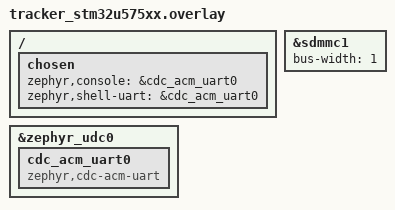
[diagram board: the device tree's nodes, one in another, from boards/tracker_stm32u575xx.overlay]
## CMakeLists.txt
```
cmake_minimum_required(VERSION 3.20.0)
find_package(Zephyr REQUIRED HINTS $ENV{ZEPHYR_BASE})
project(sdcard_usb_sample)

target_sources(app PRIVATE src/main.c)
```

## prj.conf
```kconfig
# Console over USB CDC ACM
CONFIG_LOG=y
CONFIG_SERIAL=y
CONFIG_CONSOLE=y
CONFIG_UART_CONSOLE=y
CONFIG_UART_LINE_CTRL=y

# GPIO (card detect)
CONFIG_GPIO=y

# Power domains (3V3 rail for SD card)
CONFIG_PM_DEVICE=y
CONFIG_PM_DEVICE_RUNTIME=y
CONFIG_PM_DEVICE_POWER_DOMAIN=y
CONFIG_TIMEOUT_64BIT=y
CONFIG_POWER_DOMAIN=y
CONFIG_POWER_DOMAIN_GPIO_INIT_PRIORITY=1

# Disk / SD card
CONFIG_DISK_ACCESS=y
CONFIG_SDMMC_SUBSYS=y
CONFIG_SDMMC_STM32=y

# FAT filesystem (optional — for on-device access alongside USB)
CONFIG_FILE_SYSTEM=y
CONFIG_FAT_FILESYSTEM_ELM=y

# USB — composite: CDC ACM console + mass storage SD card
CONFIG_USB_DEVICE_STACK=y
CONFIG_USB_DEVICE_PRODUCT="Tracker SD Card"
CONFIG_USB_DEVICE_VID=0x0483
CONFIG_USB_DEVICE_PID=0x0001
CONFIG_USB_CDC_ACM=y
CONFIG_USB_MASS_STORAGE=y
CONFIG_MASS_STORAGE_DISK_NAME="SD"
```

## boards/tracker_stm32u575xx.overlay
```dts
/*
 * Route console/log output to USB CDC ACM on the Tracker board.
 */

&zephyr_udc0 {
	cdc_acm_uart0: cdc_acm_uart0 {
		compatible = "zephyr,cdc-acm-uart";
	};
};

/ {
	chosen {
		zephyr,console = &cdc_acm_uart0;
		zephyr,shell-uart = &cdc_acm_uart0;
	};
};

/* Try 1-bit bus width to diagnose signal integrity issues.
 * If errors go away, the D1/D2/D3 lines have a problem.
 * Restore to 4 once hardware is confirmed good. */
&sdmmc1 {
	bus-width = <1>;
};
```

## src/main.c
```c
/*
 * SD-card counter sample
 *
 * Mounts the SD card FAT filesystem and appends an incrementing
 * counter value once per second.
 *
 * SPDX-License-Identifier: Apache-2.0
 */

#include <zephyr/kernel.h>
#include <zephyr/device.h>
#include <zephyr/storage/disk_access.h>
#include <zephyr/fs/fs.h>
#include <ff.h>
#include <zephyr/pm/device_runtime.h>
#include <zephyr/logging/log.h>

LOG_MODULE_REGISTER(sdcard_counter, LOG_LEVEL_INF);

static FATFS fat_fs;

static struct fs_mount_t mp = {
	.type = FS_FATFS,
	.fs_data = &fat_fs,
	.mnt_point = "/SD:",
};

int main(void)
{
	int ret;
	uint32_t count = 0;

	/* Power up the 3V3 rail (SD card, LoRa, sensors) */
	pm_device_runtime_get(DEVICE_DT_GET(DT_NODELABEL(power_3v3)));

	LOG_INF("SD-card counter sample");

	/* Give the SD card time to stabilise after 3V3 power-on. */
	k_msleep(100);

	/* Check that the SD card is accessible */
	ret = disk_access_init("SD");
	if (ret) {
		LOG_ERR("disk_access_init(SD) failed: %d — is a card inserted?", ret);
		return ret;
	}

	/* Mount the FAT filesystem */
	ret = fs_mount(&mp);
	if (ret) {
		LOG_ERR("fs_mount failed: %d", ret);
		return ret;
	}

	LOG_INF("SD card mounted at %s", mp.mnt_point);

	while (1) {
		struct fs_file_t file;
		char buf[32];

		fs_file_t_init(&file);

		ret = fs_open(&file, "/SD:/count.txt",
			      FS_O_CREATE | FS_O_WRITE | FS_O_APPEND);
		if (ret) {
			LOG_ERR("fs_open failed: %d", ret);
		} else {
			int len = snprintf(buf, sizeof(buf), "%u\n", count);

			ret = fs_write(&file, buf, len);
			if (ret < 0) {
				LOG_ERR("fs_write failed: %d", ret);
			} else {
				LOG_INF("Wrote count %u", count);
			}
			fs_close(&file);
		}

		count++;
		k_sleep(K_SECONDS(1));
	}

	return 0;
}
```
